# STM32H7R register map
File version: 1.3
CPU: CM7 r0p1, little endian, MPU, FPU, 4 interrupt priority bits
Registers are 32-bit, read-write, reset 0x0 unless marked. A register's access mark holds for its fields unless they carry their own. Offsets are from the block's base; [hi:lo] are bit positions; lines under a group give offsets from that group; {n}, {i} and the like mark numbered series.

## LTDC — LTDC register block
Base 0x50001000
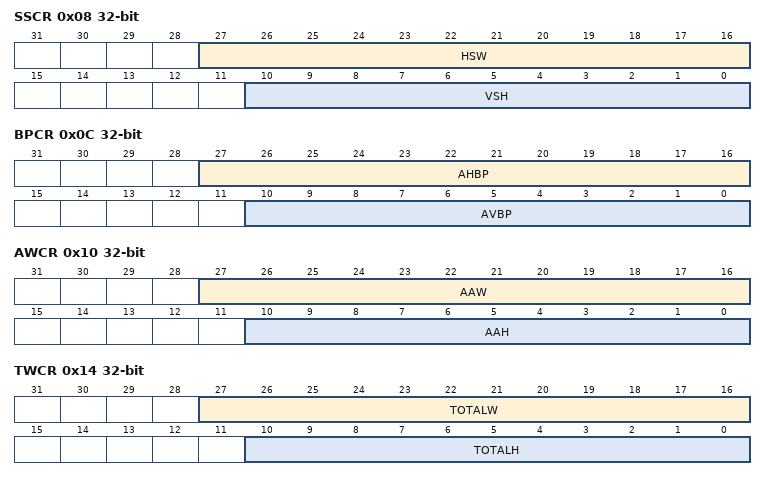
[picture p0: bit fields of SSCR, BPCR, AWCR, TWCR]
0x08 SSCR — LTDC synchronization size configuration register
  [27:16] HSW — horizontal synchronization width (in units of pixel clock period) These bits define the number of Horizontal Synchronization pixel minus 1.
  [10:0] VSH — vertical synchronization height (in units of horizontal scan line) These bits define the vertical Synchronization height minus 1. It represents the number of horizontal synchronization lines.
0x0C BPCR — LTDC back porch configuration register
  [27:16] AHBP — accumulated horizontal back porch (in units of pixel clock period) These bits define the accumulated horizontal back porch width that includes the horizontal synchronization and horizontal back porch pixels minus 1. The horizontal back porch is the period between horizontal synchronization going inactive and the start of the active display part of the next scan line.
  [10:0] AVBP — accumulated Vertical back porch (in units of horizontal scan line) These bits define the accumulated vertical back porch width that includes the vertical synchronization and vertical back porch lines minus 1. The vertical back porch is the number of horizontal scan lines at a start of frame to the start of the first active scan line of the next frame.
0x10 AWCR — LTDC active width configuration register
  [27:16] AAW — accumulated active width (in units of pixel clock period) These bits define the accumulated active width which includes the horizontal synchronization, horizontal back porch and active pixels minus 1. The active width is the number of pixels in active display area of the panel scan line. Refer to device datasheet for maximum active width supported following maximum pixel clock.
  [10:0] AAH — accumulated active height (in units of horizontal scan line) These bits define the accumulated height which includes the vertical synchronization, vertical back porch and the active height lines minus 1. The active height is the number of active lines in the panel. Refer to device datasheet for maximum active height supported following maximum pixel clock.
0x14 TWCR — LTDC total width configuration register
  [27:16] TOTALW — total width (in units of pixel clock period) These bits defines the accumulated total width which includes the horizontal synchronization, horizontal back porch, active width and horizontal front porch pixels minus 1.
  [10:0] TOTALH — total height (in units of horizontal scan line) These bits defines the accumulated height which includes the vertical synchronization, vertical back porch, the active height and vertical front porch height lines minus 1.
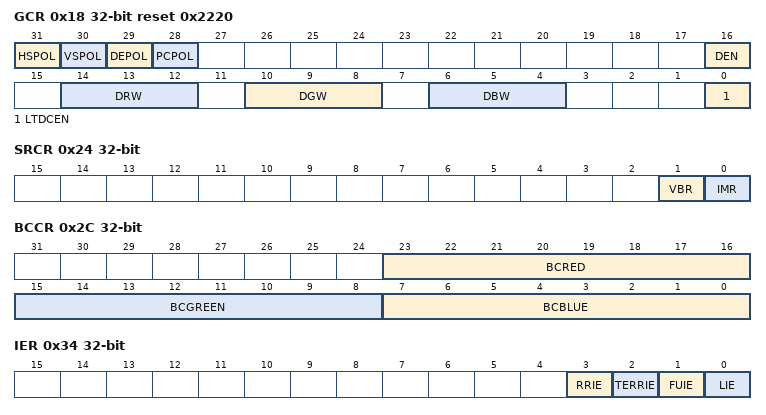
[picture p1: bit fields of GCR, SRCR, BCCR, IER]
0x18 GCR access per field reset 0x2220 — LTDC global control register
  [31] HSPOL rw — horizontal synchronization polarity This bit is set and cleared by software.
    0=ActiveLow (Horizontal synchronization polarity is active low); 1=ActiveHigh (Horizontal synchronization polarity is active high)
  [30] VSPOL rw — vertical synchronization polarity This bit is set and cleared by software.
    0=ActiveLow (Vertical synchronization polarity is active low); 1=ActiveHigh (Vertical synchronization polarity is active high)
  [29] DEPOL rw — not data enable polarity This bit is set and cleared by software.
    0=ActiveLow (Data enable polarity is active low); 1=ActiveHigh (Data enable polarity is active high)
  [28] PCPOL rw — pixel clock polarity This bit is set and cleared by software.
    0=RisingEdge (Pixel clock on rising edge); 1=FallingEdge (Pixel clock on falling edge)
  [16] DEN rw — dither enable This bit is set and cleared by software.
    0=Disabled (Dither disabled); 1=Enabled (Dither enabled)
  [14:12] DRW ro — dither red width These bits return the Dither Red Bits.
  [10:8] DGW ro — dither green width These bits return the dither green bits.
  [6:4] DBW ro — dither blue width These bits return the dither blue bits.
  [0] LTDCEN rw — LCD-TFT controller enable This bit is set and cleared by software.
    0=Disabled (LCD-TFT controller disabled); 1=Enabled (LCD-TFT controller enabled)
0x24 SRCR — LTDC shadow reload configuration register
  [1] VBR — vertical blanking reload This bit is set by software and cleared only by hardware after reload (it cannot be cleared through register write once it is set).
    0=NoEffect (This bit is set by software and cleared only by hardware after reload (it cannot be cleared through register write once it is set)); 1=Reload (The shadow registers are reloaded during the vertical blanking period (at the beginning of the first line after the active display area).)
  [0] IMR — immediate reload This bit is set by software and cleared only by hardware after reload.
    0=NoEffect (This bit is set by software and cleared only by hardware after reload (it cannot be cleared through register write once it is set)); 1=Reload (The shadow registers are reloaded immediately. This bit is set by software and cleared only by hardware after reload)
0x2C BCCR — LTDC background color configuration register
  [23:16] BCRED — background color red value These bits configure the background red value.
  [15:8] BCGREEN — background color green value These bits configure the background green value.
  [7:0] BCBLUE — background color blue value These bits configure the background blue value.
0x34 IER — LTDC interrupt enable register
  [3] RRIE — register reload interrupt enable This bit is set and cleared by software.
    0=Disabled (Register reload interrupt disabled); 1=Enabled (Register reload interrupt enabled)
  [2] TERRIE — transfer error interrupt enable This bit is set and cleared by software.
    0=Disabled (Transfer error interrupt disabled); 1=Enabled (Transfer error interrupt enabled)
  [1] FUIE — FIFO underrun interrupt enable This bit is set and cleared by software.
    0=Disabled (FIFO underrun interrupt disabled); 1=Enabled (FIFO underrun interrupt enabled)
  [0] LIE — line interrupt enable This bit is set and cleared by software.
    0=Disabled (Line interrupt disabled); 1=Enabled (Line interrupt enabled)
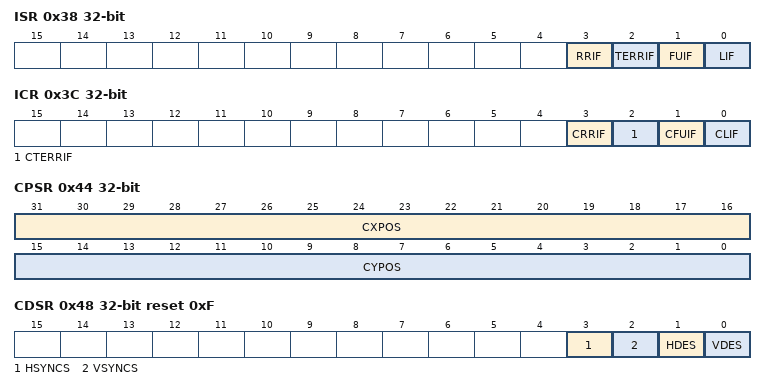
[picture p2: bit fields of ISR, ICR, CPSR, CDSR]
0x38 ISR ro — LTDC interrupt status register
  [3] RRIF — register reload interrupt flag
    0=NoReload (No register reload); 1=Reload (Register reload interrupt generated when a vertical blanking reload occurs (and the first line after the active area is reached))
  [2] TERRIF — transfer error interrupt flag
    0=NoError (No transfer error); 1=Error (Transfer error interrupt generated when a bus error occurs)
  [1] FUIF — FIFO underrun interrupt flag
    0=NoUnderrun (No FIFO underrun); 1=Underrun (FIFO underrun interrupt generated, if one of the layer FIFOs is empty and pixel data is read from the FIFO)
  [0] LIF — line interrupt flag
    0=NotReached (Programmed line not reached); 1=Reached (Line interrupt generated when a programmed line is reached)
0x3C ICR wo — LTDC interrupt clear register
  [3] CRRIF write-1-clears — clears register reload interrupt flag
    1=Clears the RRIF flag in the ISR register
  [2] CTERRIF write-1-clears — clears the transfer error interrupt flag
    1=Clears the TERRIF flag in the ISR register
  [1] CFUIF write-1-clears — clears the FIFO underrun interrupt flag
    1=Clears the FUIF flag in the ISR register
  [0] CLIF write-1-clears — clears the line interrupt flag
    1=Clears the LIF flag in the ISR register
0x40 LIPCR — LTDC line interrupt position configuration register
  [10:0] LIPOS — line interrupt position These bits configure the line interrupt position.
0x44 CPSR ro — LTDC current position status register
  [31:16] CXPOS — current X position These bits return the current X position.
  [15:0] CYPOS — current Y position These bits return the current Y position.
0x48 CDSR ro reset 0xF — LTDC current display status register
  [3] HSYNCS — horizontal synchronization display status
    0=NotActive (Currently not in HSYNC phase); 1=Active (Currently in HSYNC phase)
  [2] VSYNCS — vertical synchronization display status
    0=NotActive (Currently not in VSYNC phase); 1=Active (Currently in VSYNC phase)
  [1] HDES — horizontal data enable display status
    0=NotActive (Currently not in horizontal Data Enable phase); 1=Active (Currently in horizontal Data Enable phase)
  [0] VDES — vertical data enable display status
    0=NotActive (Currently not in vertical Data Enable phase); 1=Active (Currently in vertical Data Enable phase)
{0x4+0x80*i} LAYER{i} (i=1..2) group — Cluster LAYER{i}, containing L?CR, L?WHPCR, L?WVPCR, L?CKCR, L?PFCR, L?CACR, L?DCCR, L?BFCR, L?CFBAR, L?CFBLR, L?CFBLNR, L?CLUTWR
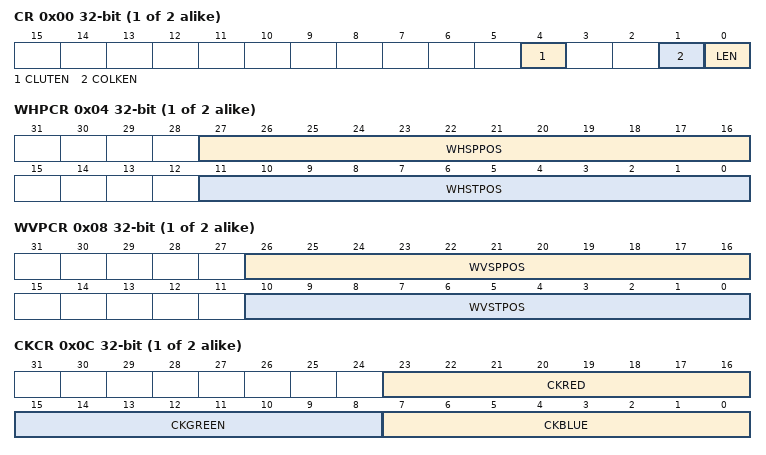
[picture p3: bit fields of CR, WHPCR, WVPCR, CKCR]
  0x00 CR — LTDC layer 1 control register
    [4] CLUTEN — color look-up table enable This bit is set and cleared by software. The CLUT is only meaningful for L8, AL44 and AL88 pixel format. Refer to Color look-up table (CLUT)
      0=Disabled (Color look-up table disabled); 1=Enabled (Color look-up table enabled)
    [1] COLKEN — color keying enable This bit is set and cleared by software.
      0=Disabled (Color keying disabled); 1=Enabled (Color keying enabled)
    [0] LEN — layer enable This bit is set and cleared by software.
      0=Disabled (Layer disabled); 1=Enabled (Layer enabled)
  0x04 WHPCR — LTDC layer 1 window horizontal position configuration register
    [27:16] WHSPPOS — window horizontal stop position These bits configure the last visible pixel of a line of the layer window. WHSPPOS[11:0] must be more or equal to AHBP[11:0] bits + 1 (programmed in LTDC_BPCR register).
    [11:0] WHSTPOS — window horizontal start position These bits configure the first visible pixel of a line of the layer window. WHSTPOS[11:0] must be UNDER OR EQUAL AAW[11:0] bits (programmed in LTDC_AWCR register).
  0x08 WVPCR — LTDC layer 1 window vertical position configuration register
    [26:16] WVSPPOS — window vertical stop position These bits configure the last visible line of the layer window. WVSPPOS[10:0] must be more or equal to AVBP[10:0] bits + 1 (programmed in LTDC_BPCR register).
    [10:0] WVSTPOS — window vertical start position These bits configure the first visible line of the layer window. WVSTPOS[10:0] must be UNDER OR EQUAL AAH[10:0] bits (programmed in LTDC_AWCR register).
  0x0C CKCR — LTDC layer 1 color keying configuration register
    [23:16] CKRED — color key red value
    [15:8] CKGREEN — color key green value
    [7:0] CKBLUE — color key blue value
  0x10 PFCR — LTDC layer 1 pixel format configuration register
    [2:0] PF — pixel format These bits configure the pixel format
      0=ARGB8888; 1=RGB888; 2=RGB565; 3=ARGB1555; 4=ARGB4444; 5=L8 (L8 (8-bit luminance)); 6=AL44 (AL44 (4-bit alpha, 4-bit luminance)); 7=AL88 (AL88 (8-bit alpha, 8-bit luminance))
  0x14 CACR reset 0xFF — LTDC layer 1 constant alpha configuration register
    [7:0] CONSTA — constant alpha These bits configure the constant alpha used for blending. The constant alpha is divided by 255 by hardware. Example: if the programmed constant alpha is 0xFF, the constant alpha value is 255 / 255 = 1.
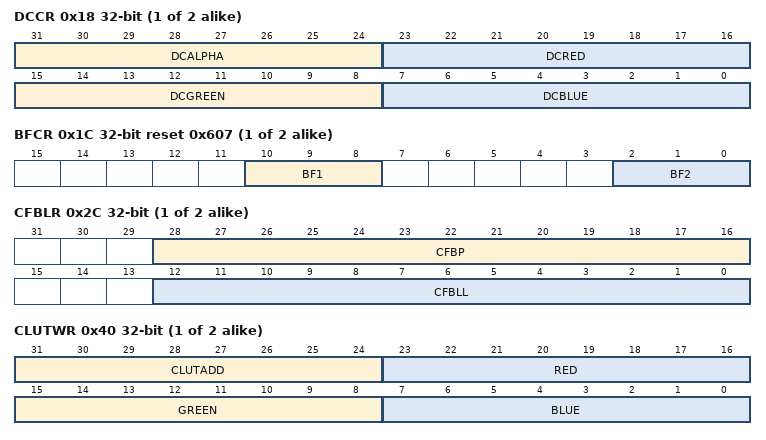
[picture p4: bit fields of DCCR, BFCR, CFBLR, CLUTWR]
  0x18 DCCR — LTDC layer 1 default color configuration register
    [31:24] DCALPHA — default color alpha These bits configure the default alpha value.
    [23:16] DCRED — default color red These bits configure the default red value.
    [15:8] DCGREEN — default color green These bits configure the default green value.
    [7:0] DCBLUE — default color blue These bits configure the default blue value.
  0x1C BFCR reset 0x607 — LTDC layer 1 blending factors configuration register
    [10:8] BF1 — blending factor 1 These bits select the blending factor F1.
      4=Constant (BF1 = constant alpha); 6=Pixel (BF1 = pixel alpha * constant alpha)
    [2:0] BF2 — blending factor 2 These bits select the blending factor F2
      5=Constant (BF2 = 1 - constant alpha); 7=Pixel (BF2 = 1 - pixel alpha * constant alpha)
  0x28 CFBAR — LTDC layer 1 color frame buffer address register
    [31:0] CFBADD — color frame buffer start address These bits define the color frame buffer start address.
  0x2C CFBLR — LTDC layer 1 color frame buffer length register
    [28:16] CFBP — color frame buffer pitch in bytes These bits define the pitch that is the increment from the start of one line of pixels to the start of the next line in bytes.
    [12:0] CFBLL — color frame buffer line length These bits define the length of one line of pixels in bytes + 7. The line length is computed as follows: active high width * number of bytes per pixel + 7.
  0x30 CFBLNR — LTDC layer 1 color frame buffer line number register
    [10:0] CFBLNBR — frame buffer line number These bits define the number of lines in the frame buffer that corresponds to the active high width.
  0x40 CLUTWR wo — LTDC layer 1 CLUT write register
    [31:24] CLUTADD — CLUT address These bits configure the CLUT address (color position within the CLUT) of each RGB value.
    [23:16] RED — red value These bits configure the red value.
    [15:8] GREEN — green value These bits configure the green value.
    [7:0] BLUE — blue value These bits configure the blue value.
